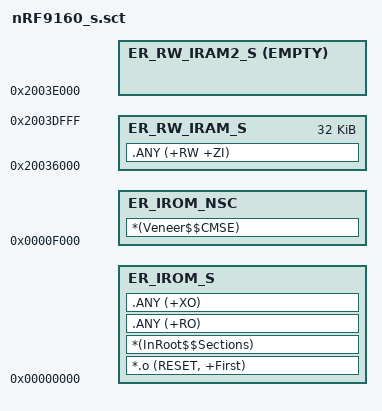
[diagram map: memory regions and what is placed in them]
; *************************************************************
; *** Scatter-Loading Description File generated by uVision ***
; *************************************************************

LR_IROM_S 0x00000000 0x0000f000 ; load region size_region
{
    ER_IROM_S +0 ; load address = execution address
    {
        *.o (RESET, +First)
        *(InRoot$$Sections)
        .ANY (+RO)
        .ANY (+XO)
    }
	
	ER_RW_IRAM_S 0x20036000 0x00008000 ; RW data
    {
        .ANY (+RW +ZI)
    }
	
	ER_RW_IRAM2_S 0x2003e000 EMPTY 0x0
	{
	}
}
	
LR_IROM_NSC 0x0000F000 0x00001000
{
    ER_IROM_NSC +0 ; load address = execution address
    {
        *(Veneer$$CMSE)
    }
}
